# STM32H7R7xx register map
File version: 1.0
Registers are 32-bit, read-write, reset 0x0 unless marked. A register's access mark holds for its fields unless they carry their own. Offsets are from the block's base; [hi:lo] are bit positions; {n}, {i} and the like mark numbered series.

## TAMP — Tamper and backup registers
Base 0x58004400
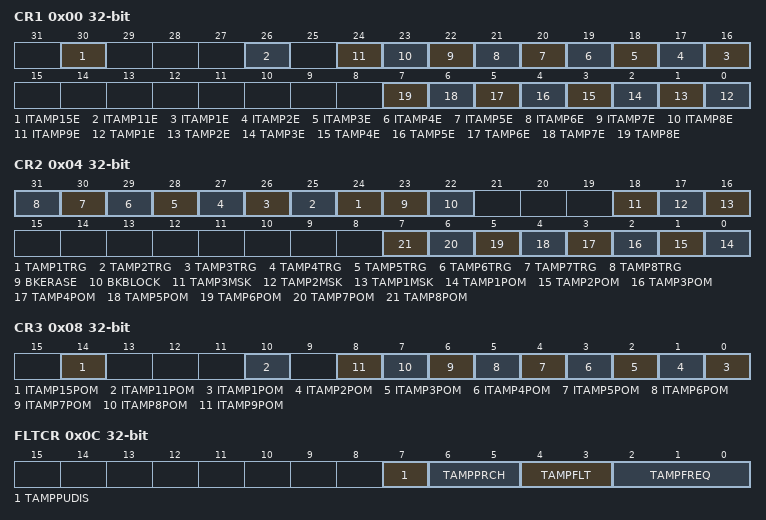
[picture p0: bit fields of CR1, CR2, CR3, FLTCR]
0x00 CR1 — TAMP configuration register 1
  [30] ITAMP15E, [26] ITAMP11E, [n+15] ITAMP{n}E (n=1..9), [n-1] TAMP{n}E (n=1..8)
0x04 CR2 — TAMP configuration register 2
  [n+23] TAMP{n}TRG (n=1..8), [23] BKERASE, [22] BKBLOCK, [18] TAMP3MSK, [17] TAMP2MSK, [16] TAMP1MSK, [n-1] TAMP{n}POM (n=1..8)
0x08 CR3 — TAMP configuration register 3
  [14] ITAMP15POM, [10] ITAMP11POM, [n-1] ITAMP{n}POM (n=1..9)
0x0C FLTCR — TAMP filter control register
  [7] TAMPPUDIS
  [6:5] TAMPPRCH
    0=DURATION_1RTCCLK (Tamper pins are pre-charged before sampling during 1 RTCCLK cycle); 1=DURATION_2RTCCLK (Tamper pins are pre-charged before sampling during 2 RTCCLK cycles); 2=DURATION_4RTCCLK (Tamper pins are pre-charged before sampling during 4 RTCCLK cycles); 3=DURATION_8RTCCLK (Tamper pins are pre-charged before sampling during 8 RTCCLK cycles)
  [4:3] TAMPFLT
    0=DISABLE (Tamper filter is disabled); 1=FILTER_2SAMPLE (Tamper is activated after 2 consecutive samples at the active level); 2=FILTER_4SAMPLE (Tamper is activated after 4 consecutive samples at the active level); 3=FILTER_8SAMPLE (Tamper is activated after 8 consecutive samples at the active level)
  [2:0] TAMPFREQ
    0=SAMPLFREQDIV_32768 (Each of the tamper inputs are sampled with a frequency = RTCCLK / 32768); 1=SAMPLFREQDIV_16384 (Each of the tamper inputs are sampled with a frequency = RTCCLK / 16384); 2=SAMPLFREQDIV_8192 (Each of the tamper inputs are sampled with a frequency = RTCCLK / 8192); 3=SAMPLFREQDIV_4096 (Each of the tamper inputs are sampled with a frequency = RTCCLK / 4096); 4=SAMPLFREQDIV_2048 (Each of the tamper inputs are sampled with a frequency = RTCCLK / 2048); 5=SAMPLFREQDIV_1024 (Each of the tamper inputs are sampled with a frequency = RTCCLK / 1024); 6=SAMPLFREQDIV_512 (Each of the tamper inputs are sampled with a frequency = RTCCLK / 512); 7=SAMPLFREQDIV_256 (Each of the tamper inputs are sampled with a frequency = RTCCLK / 256)
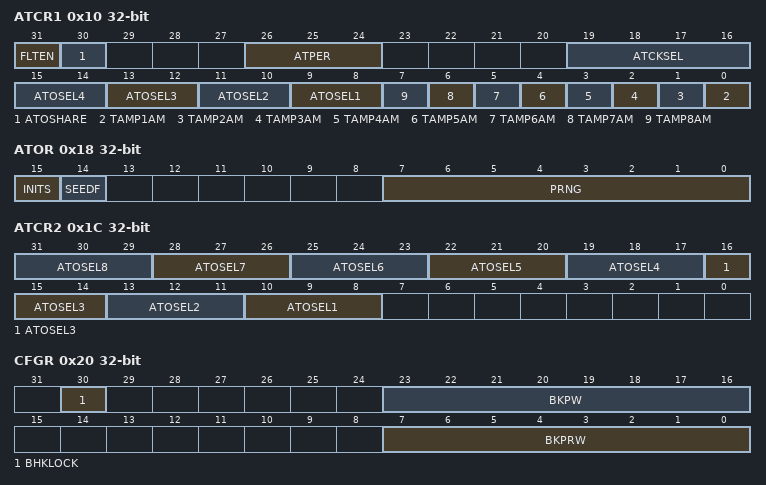
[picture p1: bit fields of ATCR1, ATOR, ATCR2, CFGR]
0x10 ATCR1 — TAMP filter control register 1
  [31] FLTEN, [30] ATOSHARE, [26:24] ATPER, [19:16] ATCKSEL, [2n+7:2n+6] ATOSEL{n} (n=1..4), [n-1] TAMP{n}AM (n=1..8)
0x14 ATSEEDR — TAMP active tamper seed register
  [31:0] SEED
0x18 ATOR — TAMP active tamper output register
  [15] INITS, [14] SEEDF, [7:0] PRNG
0x1C ATCR2 — TAMP filter control register 2
  [3n+7:3n+5] ATOSEL{n} (n=1..8)
0x20 CFGR — TAMP configuration control register
  [30] BHKLOCK, [23:16] BKPW, [7:0] BKPRW
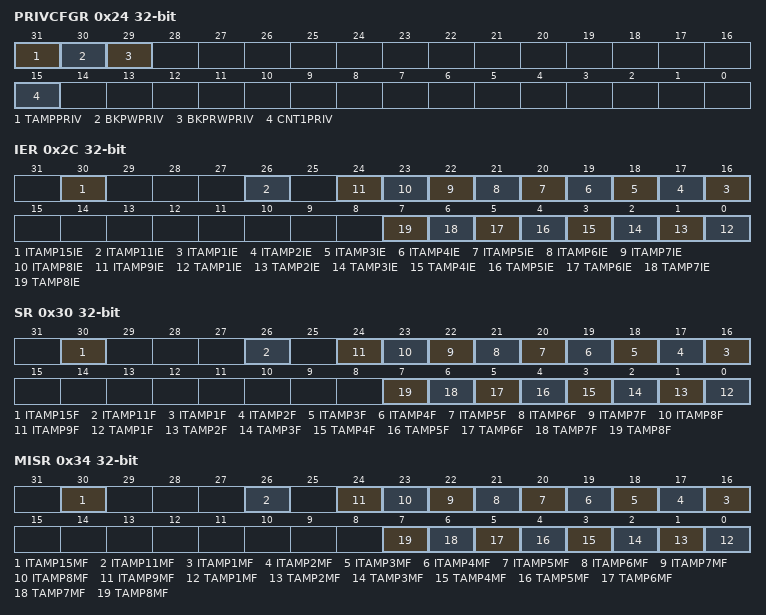
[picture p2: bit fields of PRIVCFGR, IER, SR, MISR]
0x24 PRIVCFGR — TAMP privilege mode control register
  [31] TAMPPRIV
    1=YES (TAMP full privilege); 0=NO (TAMP is not privilege)
  [30] BKPWPRIV
  [29] BKPRWPRIV
  [15] CNT1PRIV
0x2C IER — TAMP interrupt enable register
  [30] ITAMP15IE, [26] ITAMP11IE, [n+15] ITAMP{n}IE (n=1..9), [n-1] TAMP{n}IE (n=1..8)
0x30 SR — TAMP status register
  [30] ITAMP15F, [26] ITAMP11F, [n+15] ITAMP{n}F (n=1..9), [n-1] TAMP{n}F (n=1..8)
0x34 MISR — TAMP masked interrupt status register
  [30] ITAMP15MF, [26] ITAMP11MF, [n+15] ITAMP{n}MF (n=1..9), [n-1] TAMP{n}MF (n=1..8)
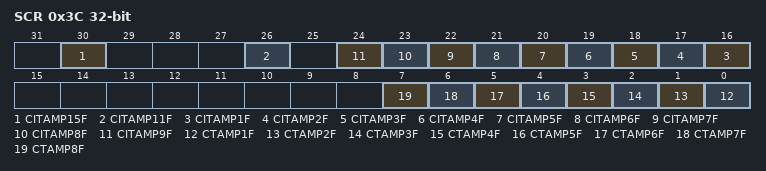
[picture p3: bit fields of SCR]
0x3C SCR — TAMP status clear register
  [30] CITAMP15F, [26] CITAMP11F, [n+15] CITAMP{n}F (n=1..9), [n-1] CTAMP{n}F (n=1..8)
0x40 COUNT1R — TAMP monotonic counter 1 register
  [31:0] COUNT
0x54 RPCFGR — TAMP resources protection configuration register
  [0] RPCFG0
{0x100+4i} BKP{i}R (i=0..31) — TAMP backup register {i}

## IWDG
Base 0x58004800
0x00 KR — IWDG Key register
  [15:0] KEY — Key value (write only, read 0000h)
0x04 PR — IWDG Prescaler register
  [3:0] PR — PR[3:0] (Prescaler divider)
0x08 RLR — IWDG Reload register
  [11:0] RL — Watchdog counter reload value
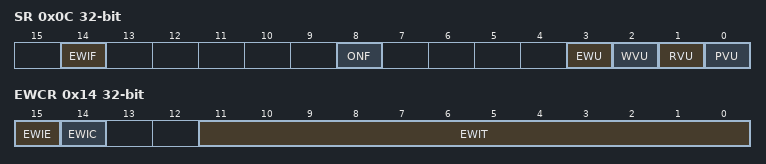
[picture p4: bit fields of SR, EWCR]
0x0C SR — IWDG Status register
  [14] EWIF — Watchdog early interrupt flag
  [8] ONF — Watchdog enable flag
  [3] EWU — Watchdog interrupt comparator value update
  [2] WVU — Watchdog counter window value update
  [1] RVU — Watchdog counter reload value update
  [0] PVU — Watchdog prescaler value update
0x10 WINR — IWDG Window register
  [11:0] WIN — Watchdog counter window value
0x14 EWCR — IWDG Early Wakeup register
  [15] EWIE — Watchdog early interrupt enable
  [14] EWIC — Watchdog early interrupt acknowledge
  [11:0] EWIT — Watchdog early wakeup comparator value
